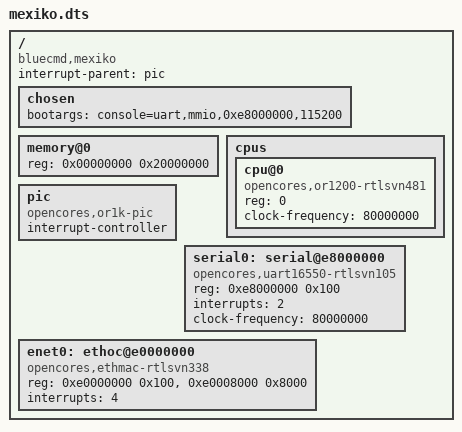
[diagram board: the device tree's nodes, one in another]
/dts-v1/;
/ {
	compatible = "bluecmd,mexiko";
	#address-cells = <1>;
	#size-cells = <1>;
	interrupt-parent = <&pic>;

	chosen {
		bootargs = "console=uart,mmio,0xe8000000,115200";
	};

	memory@0 {
		device_type = "memory";
		reg = <0x00000000 0x20000000>;
	};

	cpus {
		#address-cells = <1>;
		#size-cells = <0>;
		cpu@0 {
			compatible = "opencores,or1200-rtlsvn481";
			reg = <0>;
			clock-frequency = <80000000>;
		};
	};

	/*
	 * OR1K PIC is built into CPU and accessed via special purpose
	 * registers.  It is not addressable and, hence, has no 'reg'
	 * property.
	 */
	pic: pic {
		compatible = "opencores,or1k-pic";
		#interrupt-cells = <1>;
		interrupt-controller;
	};

	serial0: serial@e8000000 {
		compatible = "opencores,uart16550-rtlsvn105", "ns16550a";
		reg = <0xe8000000 0x100>;
		interrupts = <2>;
		clock-frequency = <80000000>;
	};

	enet0: ethoc@e0000000 {
		compatible = "opencores,ethmac-rtlsvn338";
		reg = <0xe0000000 0x100>, <0xe0008000 0x8000>;
		interrupts = <4>;
	};
};
